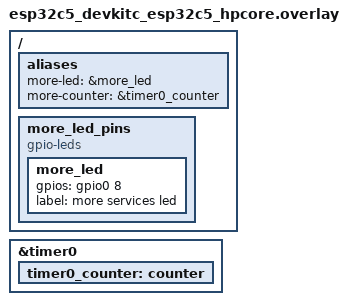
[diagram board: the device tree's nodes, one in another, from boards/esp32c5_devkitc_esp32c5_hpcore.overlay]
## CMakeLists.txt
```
# SPDX-License-Identifier: Apache-2.0

cmake_minimum_required(VERSION 3.20.0)
find_package(Zephyr REQUIRED HINTS $ENV{ZEPHYR_BASE})
project(app_more_services)

zephyr_syscall_header(${CMAKE_CURRENT_SOURCE_DIR}/src/svc.h)

target_sources(app PRIVATE src/main.c src/svc.c)
```

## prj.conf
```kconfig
CONFIG_USERSPACE=y
CONFIG_APPLICATION_DEFINED_SYSCALL=y

CONFIG_GPIO=y
CONFIG_COUNTER=y
CONFIG_ENTROPY_GENERATOR=y

CONFIG_LOG=y
CONFIG_LOG_MODE_MINIMAL=y
CONFIG_THREAD_NAME=y

CONFIG_MAIN_STACK_SIZE=4096
```

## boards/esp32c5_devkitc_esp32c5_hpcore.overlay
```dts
/*
 * Copyright (c) 2026 Espressif Systems (Shanghai) Co., Ltd.
 *
 * SPDX-License-Identifier: Apache-2.0
 */

/ {
	aliases {
		more-led = &more_led;
		more-counter = &timer0_counter;
	};

	more_led_pins {
		compatible = "gpio-leds";

		more_led: more_led {
			gpios = <&gpio0 8 GPIO_ACTIVE_HIGH>;
			label = "more services led";
		};
	};
};

&timer0 {
	status = "okay";

	timer0_counter: counter {
		status = "okay";
	};
};
```

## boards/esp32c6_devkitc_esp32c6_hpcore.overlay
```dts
/*
 * Copyright (c) 2026 Espressif Systems (Shanghai) Co., Ltd.
 *
 * SPDX-License-Identifier: Apache-2.0
 */

/ {
	aliases {
		more-led = &more_led;
		more-counter = &timer0_counter;
	};

	more_led_pins {
		compatible = "gpio-leds";

		more_led: more_led {
			gpios = <&gpio0 8 GPIO_ACTIVE_HIGH>;
			label = "more services led";
		};
	};
};

/* Enable a hardware timer + its counter for the one-shot timer service. */
&timer0 {
	status = "okay";

	timer0_counter: counter {
		status = "okay";
	};
};
```

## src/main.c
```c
/*
 * Copyright (c) 2026 Espressif Systems (Shanghai) Co., Ltd.
 *
 * SPDX-License-Identifier: Apache-2.0
 */

/*
 * An app that uses a broad set of platform services, each a different Zephyr
 * subsystem: the hardware RNG, GPIO input (button) and output (LED), a hardware
 * counter used as a one-shot timer with its expiry delivered to the app, and
 * the system time. The app runs in user mode and reaches all of it only through
 * service syscalls.
 */

#include "svc.h"

#include <zephyr/kernel.h>
#include <zephyr/sys/printk.h>

#define STACK_SIZE 2048
#define APP_PRIO   5

extern void svc_init(void);

K_THREAD_STACK_DEFINE(app_stack, STACK_SIZE);
static struct k_thread app_thread;

static void app_entry(void *p1, void *p2, void *p3)
{
	ARG_UNUSED(p1); ARG_UNUSED(p2); ARG_UNUSED(p3);

	/* RNG: hardware entropy. */
	uint8_t r[4];

	svc_random(r, sizeof(r));
	printk("  [app] random bytes: %02x %02x %02x %02x\n",
	       r[0], r[1], r[2], r[3]);

	/* Time. */
	printk("  [app] uptime=%u ms, cycles=%u\n", svc_uptime(), svc_cycles());

	/* GPIO out: blink the LED a few times. */
	printk("  [app] blinking LED via GPIO service\n");
	for (int i = 0; i < 3; i++) {
		svc_led(1); k_msleep(150);
		svc_led(0); k_msleep(150);
	}

	/* GPIO in: read the button. */
	int b = svc_button();

	printk("  [app] button is %s\n",
	       b == 1 ? "PRESSED" : b == 0 ? "released" : "n/a");

	/* Hardware counter as a one-shot timer; wait for the expiry event. */
	printk("  [app] arming a 500 ms hardware timer...\n");
	if (svc_timer_start(500) == 0) {
		int rc = svc_timer_wait(2000);

		printk("  [app] timer %s (uptime now %u ms)\n",
		       rc == 0 ? "FIRED" : "did not fire", svc_uptime());
	} else {
		printk("  [app] timer start failed\n");
	}

	printk("  [app] done - touched RNG, GPIO in/out, counter, time\n");
}

int main(void)
{
	printk("\n*** more services: RNG, GPIO, hardware timer, time (C6) ***\n");
	svc_init();

	k_tid_t t = k_thread_create(&app_thread, app_stack, STACK_SIZE, app_entry,
				    NULL, NULL, NULL, APP_PRIO, K_USER, K_FOREVER);

	k_thread_start(t);
	k_thread_join(t, K_FOREVER);

	printk("\n*** done ***\n");
	return 0;
}
```

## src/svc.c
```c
/*
 * Copyright (c) 2026 Espressif Systems (Shanghai) Co., Ltd.
 *
 * SPDX-License-Identifier: Apache-2.0
 */

#include "svc.h"

#include <zephyr/kernel.h>
#include <zephyr/sys/printk.h>
#include <zephyr/device.h>
#include <zephyr/drivers/gpio.h>
#include <zephyr/drivers/counter.h>
#include <zephyr/random/random.h>
#include <zephyr/internal/syscall_handler.h>

/* Devices the platform owns. */
static const struct gpio_dt_spec button =
	GPIO_DT_SPEC_GET(DT_ALIAS(sw0), gpios);
static const struct gpio_dt_spec led =
	GPIO_DT_SPEC_GET(DT_ALIAS(more_led), gpios);
static const struct device *const counter_dev =
	DEVICE_DT_GET(DT_ALIAS(more_counter));

/* One app's timer-expiry signal (single-app demo; per-app in a full platform). */
static struct k_sem timer_sem;
static struct counter_alarm_cfg alarm;

void svc_init(void)
{
	if (gpio_is_ready_dt(&button)) {
		gpio_pin_configure_dt(&button, GPIO_INPUT);
	}
	if (gpio_is_ready_dt(&led)) {
		gpio_pin_configure_dt(&led, GPIO_OUTPUT_INACTIVE);
	}
	k_sem_init(&timer_sem, 0, 1);
	if (device_is_ready(counter_dev)) {
		counter_start(counter_dev);
	}
}

/* ---- RNG ---- */
int z_impl_svc_random(uint8_t *buf, size_t len)
{
	sys_rand_get(buf, len);
	return 0;
}

/* ---- GPIO input ---- */
int z_impl_svc_button(void)
{
	if (!gpio_is_ready_dt(&button)) {
		return -ENODEV;
	}
	return gpio_pin_get_dt(&button);
}

/* ---- GPIO output ---- */
int z_impl_svc_led(int on)
{
	if (!gpio_is_ready_dt(&led)) {
		return -ENODEV;
	}
	return gpio_pin_set_dt(&led, on ? 1 : 0);
}

/* ---- hardware counter as a one-shot timer ---- */
static void alarm_cb(const struct device *dev, uint8_t chan, uint32_t ticks,
		     void *user)
{
	ARG_UNUSED(dev); ARG_UNUSED(chan); ARG_UNUSED(ticks); ARG_UNUSED(user);
	/* Expiry arrives in ISR context; signal the app (the event seam). */
	k_sem_give(&timer_sem);
}

int z_impl_svc_timer_start(uint32_t ms)
{
	if (!device_is_ready(counter_dev)) {
		return -ENODEV;
	}
	alarm.flags = 0;
	alarm.ticks = counter_us_to_ticks(counter_dev, (uint64_t)ms * 1000);
	alarm.callback = alarm_cb;
	alarm.user_data = NULL;
	k_sem_reset(&timer_sem);
	return counter_set_channel_alarm(counter_dev, 0, &alarm);
}

int z_impl_svc_timer_wait(int32_t timeout_ms)
{
	return (k_sem_take(&timer_sem, K_MSEC(timeout_ms)) == 0) ? 0 : -EAGAIN;
}

/* ---- time ---- */
uint32_t z_impl_svc_uptime(void)
{
	return (uint32_t)k_uptime_get();
}

uint32_t z_impl_svc_cycles(void)
{
	return k_cycle_get_32();
}

#ifdef CONFIG_USERSPACE
static inline int z_vrfy_svc_random(uint8_t *buf, size_t len)
{
	K_OOPS(K_SYSCALL_MEMORY_WRITE(buf, len));
	return z_impl_svc_random(buf, len);
}
#include <zephyr/syscalls/svc_random_mrsh.c>

static inline int z_vrfy_svc_button(void)
{
	return z_impl_svc_button();
}
#include <zephyr/syscalls/svc_button_mrsh.c>

static inline int z_vrfy_svc_led(int on)
{
	return z_impl_svc_led(on);
}
#include <zephyr/syscalls/svc_led_mrsh.c>

static inline int z_vrfy_svc_timer_start(uint32_t ms)
{
	return z_impl_svc_timer_start(ms);
}
#include <zephyr/syscalls/svc_timer_start_mrsh.c>

static inline int z_vrfy_svc_timer_wait(int32_t timeout_ms)
{
	return z_impl_svc_timer_wait(timeout_ms);
}
#include <zephyr/syscalls/svc_timer_wait_mrsh.c>

static inline uint32_t z_vrfy_svc_uptime(void)
{
	return z_impl_svc_uptime();
}
#include <zephyr/syscalls/svc_uptime_mrsh.c>

static inline uint32_t z_vrfy_svc_cycles(void)
{
	return z_impl_svc_cycles();
}
#include <zephyr/syscalls/svc_cycles_mrsh.c>
#endif
```

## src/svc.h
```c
/*
 * Copyright (c) 2026 Espressif Systems (Shanghai) Co., Ltd.
 *
 * SPDX-License-Identifier: Apache-2.0
 */

#ifndef APP_MORE_SERVICES_SVC_H_
#define APP_MORE_SERVICES_SVC_H_

#include <zephyr/kernel.h>

/*
 * A broader set of app-callable services, each touching a different Zephyr
 * subsystem in its proper capability shape:
 *
 *   svc_random   - hardware RNG (open: any app)
 *   svc_button   - GPIO input, the devkit button (open: read-only)
 *   svc_led      - GPIO output (scoped in a real system; open here)
 *   svc_timer_*  - hardware counter as a one-shot timer; the expiry is delivered
 *                  to the app's event queue (arbitrated pool + async-event seam)
 *   svc_uptime   - milliseconds since boot (open)
 *   svc_cycles   - the cycle counter (open)
 */

/* Open: entropy from the hardware RNG. Fills @buf with @len random bytes. */
__syscall int svc_random(uint8_t *buf, size_t len);

/* Open: read the on-board button. Returns 1 pressed, 0 released, <0 error. */
__syscall int svc_button(void);

/* Open/scoped: set the controllable LED pin. */
__syscall int svc_led(int on);

/* Arbitrated: arm a one-shot hardware-counter timer for @ms milliseconds. The
 * expiry is posted to the calling app's event queue (poll with svc_timer_wait).
 */
__syscall int svc_timer_start(uint32_t ms);
/* Wait up to @timeout_ms for the timer to expire. 0 = expired, -EAGAIN = not. */
__syscall int svc_timer_wait(int32_t timeout_ms);

/* Open: time. */
__syscall uint32_t svc_uptime(void);
__syscall uint32_t svc_cycles(void);

#include <zephyr/syscalls/svc.h>

#endif /* APP_MORE_SERVICES_SVC_H_ */
```
